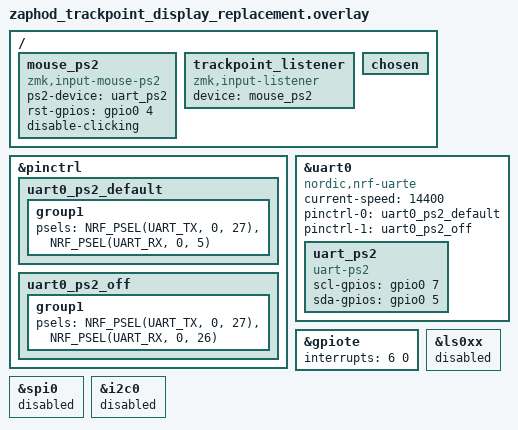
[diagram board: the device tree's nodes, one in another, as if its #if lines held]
/*
 * Copyright (c) 2026 The Zaphod Contributors
 * SPDX-License-Identifier: MIT
 */

#ifdef ZAPHOD_TRACKPOINT_SPARE_PINS
#error "Select only one Zaphod TrackPoint shield: spare pins or display replacement"
#endif
#define ZAPHOD_TRACKPOINT_REPLACES_DISPLAY 1

#include <dt-bindings/gpio/gpio.h>
#include <dt-bindings/pinctrl/nrf-pinctrl.h>

&pinctrl {
	/*
	 * The Sharp display must be physically removed. J1.5/P0.05 is DATA,
	 * J1.6/P0.07 is CLOCK, and J1.4/P0.04 is TrackPoint RESET.
	 */
	uart0_ps2_default: uart0_ps2_default {
		group1 {
			psels = <NRF_PSEL(UART_TX, 0, 27)>,
				<NRF_PSEL(UART_RX, 0, 5)>;
		};
	};

	/* Release DATA while the driver bit-bangs host-to-device commands. */
	uart0_ps2_off: uart0_ps2_off {
		group1 {
			psels = <NRF_PSEL(UART_TX, 0, 27)>,
				<NRF_PSEL(UART_RX, 0, 26)>;
		};
	};
};

/ {
	mouse_ps2: mouse_ps2 {
		compatible = "zmk,input-mouse-ps2";
		ps2-device = <&uart_ps2>;

		/* J1.4, formerly display chip select. */
		rst-gpios = <&gpio0 4 GPIO_ACTIVE_HIGH>;

		/* Keep the first keyboard integration movement-only. */
		disable-clicking;
	};

	trackpoint_listener: trackpoint_listener {
		compatible = "zmk,input-listener";
		device = <&mouse_ps2>;
	};
};

&uart0 {
	status = "okay";
	compatible = "nordic,nrf-uarte";
	current-speed = <14400>;
	pinctrl-0 = <&uart0_ps2_default>;
	pinctrl-1 = <&uart0_ps2_off>;
	pinctrl-names = "default", "sleep";

	uart_ps2: uart_ps2 {
		compatible = "uart-ps2";
		/* Open-drain is applied only in driver output mode, not DT flags. */
		scl-gpios = <&gpio0 7 GPIO_ACTIVE_HIGH>;
		sda-gpios = <&gpio0 5 GPIO_ACTIVE_HIGH>;
	};
};

/* PS/2 clock edges must preempt normal BLE controller work. */
&gpiote {
	interrupts = <6 0>;
};

/* Release all former display ownership before the PS/2 device initializes. */
/ {
    chosen {
        /delete-property/ zephyr,display;
    };
};

&ls0xx { status = "disabled"; };
&spi0 {
    status = "disabled";
    /delete-property/ pinctrl-0;
    /delete-property/ pinctrl-1;
    /delete-property/ pinctrl-names;
    /delete-property/ cs-gpios;
};
&i2c0 { status = "disabled"; };
